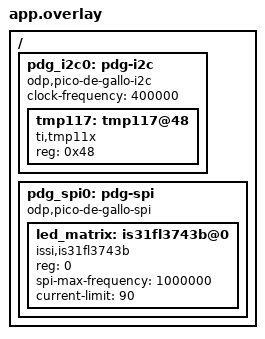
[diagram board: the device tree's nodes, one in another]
/*
 * Copyright (c) 2026 Open Device Partnership and Contributors
 *
 * SPDX-License-Identifier: MIT
 */

/ {
	pdg_i2c0: pdg-i2c {
		compatible = "odp,pico-de-gallo-i2c";
		clock-frequency = <400000>;
		#address-cells = <1>;
		#size-cells = <0>;
		status = "okay";

		tmp117: tmp117@48 {
			compatible = "ti,tmp11x";
			reg = <0x48>;
			status = "okay";
		};
	};

	pdg_spi0: pdg-spi {
		compatible = "odp,pico-de-gallo-spi";
		#address-cells = <1>;
		#size-cells = <0>;
		status = "okay";

		led_matrix: is31fl3743b@0 {
			compatible = "issi,is31fl3743b";
			reg = <0>;
			spi-max-frequency = <1000000>;
			current-limit = <90>;
			status = "okay";
		};
	};
};
